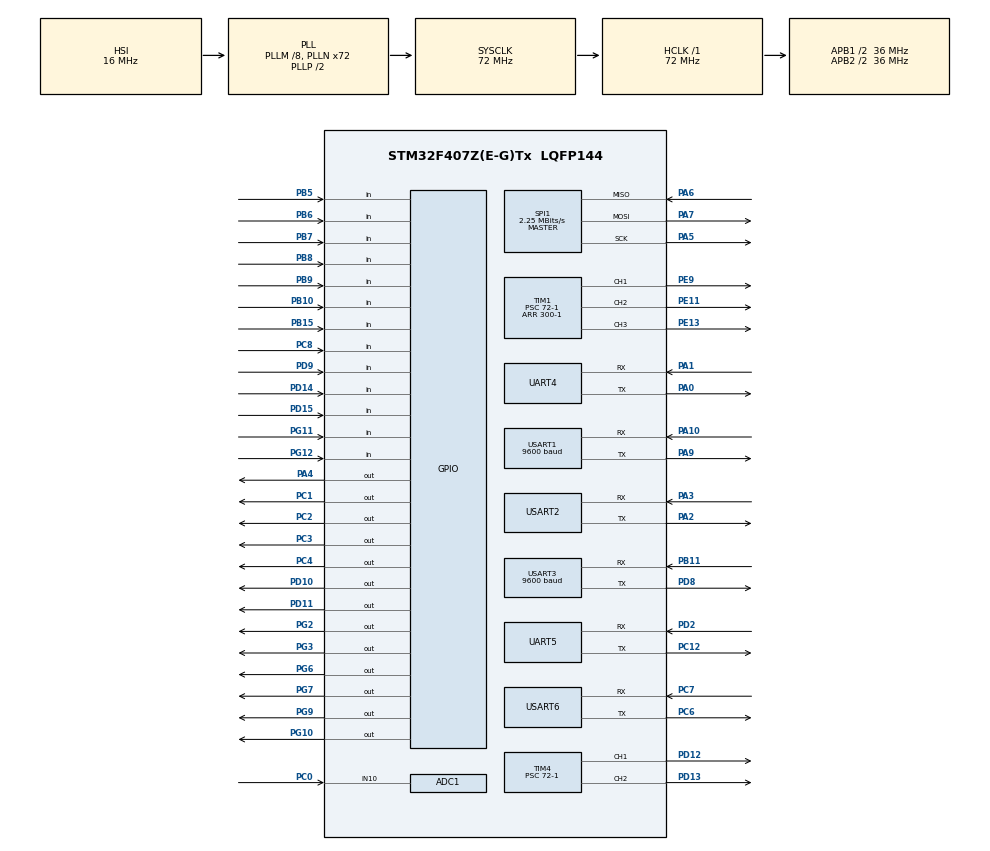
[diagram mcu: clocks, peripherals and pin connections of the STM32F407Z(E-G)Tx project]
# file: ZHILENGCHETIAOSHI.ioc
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ADC1.Channel-3\#ChannelRegularConversion=ADC_CHANNEL_10
ADC1.ContinuousConvMode=DISABLE
ADC1.NbrOfConversionFlag=1
ADC1.Rank-3\#ChannelRegularConversion=1
ADC1.SamplingTime-3\#ChannelRegularConversion=ADC_SAMPLETIME_3CYCLES
ADC1.master=1
Dma.Request0=USART2_RX
Dma.Request1=USART2_TX
Dma.Request2=UART5_RX
Dma.Request3=UART5_TX
Dma.Request4=UART4_RX
Dma.Request5=UART4_TX
Dma.Request6=USART6_RX
Dma.Request7=USART6_TX
Dma.UART4_RX.4.Direction=DMA_PERIPH_TO_MEMORY
Dma.UART4_RX.4.FIFOMode=DMA_FIFOMODE_DISABLE
Dma.UART4_RX.4.Instance=DMA1_Stream2
Dma.UART4_RX.4.MemDataAlignment=DMA_MDATAALIGN_BYTE
Dma.UART4_RX.4.MemInc=DMA_MINC_ENABLE
Dma.UART4_RX.4.Mode=DMA_NORMAL
Dma.UART4_RX.4.PeriphDataAlignment=DMA_PDATAALIGN_BYTE
Dma.UART4_RX.4.PeriphInc=DMA_PINC_DISABLE
Dma.UART4_RX.4.Priority=DMA_PRIORITY_LOW
Dma.UART4_TX.5.Direction=DMA_MEMORY_TO_PERIPH
Dma.UART4_TX.5.FIFOMode=DMA_FIFOMODE_DISABLE
Dma.UART4_TX.5.Instance=DMA1_Stream4
Dma.UART4_TX.5.MemDataAlignment=DMA_MDATAALIGN_BYTE
Dma.UART4_TX.5.MemInc=DMA_MINC_ENABLE
Dma.UART4_TX.5.Mode=DMA_NORMAL
Dma.UART4_TX.5.PeriphDataAlignment=DMA_PDATAALIGN_BYTE
Dma.UART4_TX.5.PeriphInc=DMA_PINC_DISABLE
Dma.UART4_TX.5.Priority=DMA_PRIORITY_LOW
Dma.UART5_RX.2.Direction=DMA_PERIPH_TO_MEMORY
Dma.UART5_RX.2.FIFOMode=DMA_FIFOMODE_DISABLE
Dma.UART5_RX.2.Instance=DMA1_Stream0
Dma.UART5_RX.2.MemDataAlignment=DMA_MDATAALIGN_BYTE
Dma.UART5_RX.2.MemInc=DMA_MINC_ENABLE
Dma.UART5_RX.2.Mode=DMA_NORMAL
Dma.UART5_RX.2.PeriphDataAlignment=DMA_PDATAALIGN_BYTE
Dma.UART5_RX.2.PeriphInc=DMA_PINC_DISABLE
Dma.UART5_RX.2.Priority=DMA_PRIORITY_LOW
Dma.UART5_TX.3.Direction=DMA_MEMORY_TO_PERIPH
Dma.UART5_TX.3.FIFOMode=DMA_FIFOMODE_DISABLE
Dma.UART5_TX.3.Instance=DMA1_Stream7
Dma.UART5_TX.3.MemDataAlignment=DMA_MDATAALIGN_BYTE
Dma.UART5_TX.3.MemInc=DMA_MINC_ENABLE
Dma.UART5_TX.3.Mode=DMA_NORMAL
Dma.UART5_TX.3.PeriphDataAlignment=DMA_PDATAALIGN_BYTE
Dma.UART5_TX.3.PeriphInc=DMA_PINC_DISABLE
Dma.UART5_TX.3.Priority=DMA_PRIORITY_LOW
Dma.USART2_RX.0.Direction=DMA_PERIPH_TO_MEMORY
Dma.USART2_RX.0.FIFOMode=DMA_FIFOMODE_DISABLE
Dma.USART2_RX.0.Instance=DMA1_Stream5
Dma.USART2_RX.0.MemDataAlignment=DMA_MDATAALIGN_BYTE
Dma.USART2_RX.0.MemInc=DMA_MINC_ENABLE
Dma.USART2_RX.0.Mode=DMA_NORMAL
Dma.USART2_RX.0.PeriphDataAlignment=DMA_PDATAALIGN_BYTE
Dma.USART2_RX.0.PeriphInc=DMA_PINC_DISABLE
Dma.USART2_RX.0.Priority=DMA_PRIORITY_LOW
Dma.USART2_TX.1.Direction=DMA_MEMORY_TO_PERIPH
Dma.USART2_TX.1.FIFOMode=DMA_FIFOMODE_DISABLE
Dma.USART2_TX.1.Instance=DMA1_Stream6
Dma.USART2_TX.1.MemDataAlignment=DMA_MDATAALIGN_BYTE
Dma.USART2_TX.1.MemInc=DMA_MINC_ENABLE
Dma.USART2_TX.1.Mode=DMA_NORMAL
Dma.USART2_TX.1.PeriphDataAlignment=DMA_PDATAALIGN_BYTE
Dma.USART2_TX.1.PeriphInc=DMA_PINC_DISABLE
Dma.USART2_TX.1.Priority=DMA_PRIORITY_LOW
Dma.USART6_RX.6.Direction=DMA_PERIPH_TO_MEMORY
Dma.USART6_RX.6.FIFOMode=DMA_FIFOMODE_DISABLE
Dma.USART6_RX.6.Instance=DMA2_Stream1
Dma.USART6_RX.6.MemDataAlignment=DMA_MDATAALIGN_BYTE
Dma.USART6_RX.6.MemInc=DMA_MINC_ENABLE
Dma.USART6_RX.6.Mode=DMA_NORMAL
Dma.USART6_RX.6.PeriphDataAlignment=DMA_PDATAALIGN_BYTE
Dma.USART6_RX.6.PeriphInc=DMA_PINC_DISABLE
Dma.USART6_RX.6.Priority=DMA_PRIORITY_LOW
Dma.USART6_TX.7.Direction=DMA_MEMORY_TO_PERIPH
Dma.USART6_TX.7.FIFOMode=DMA_FIFOMODE_DISABLE
Dma.USART6_TX.7.Instance=DMA2_Stream6
Dma.USART6_TX.7.MemDataAlignment=DMA_MDATAALIGN_BYTE
Dma.USART6_TX.7.MemInc=DMA_MINC_ENABLE
Dma.USART6_TX.7.Mode=DMA_NORMAL
Dma.USART6_TX.7.PeriphDataAlignment=DMA_PDATAALIGN_BYTE
Dma.USART6_TX.7.PeriphInc=DMA_PINC_DISABLE
Dma.USART6_TX.7.Priority=DMA_PRIORITY_LOW
Mcu.Family=STM32F4
Mcu.Name=STM32F407Z(E-G)Tx
Mcu.Package=LQFP144
NVIC.DMA1_Stream0_IRQn=true\:0\:0\:false\:false\:true\:false\:true\:true
NVIC.DMA1_Stream2_IRQn=true\:0\:0\:false\:false\:true\:false\:true\:true
NVIC.DMA1_Stream4_IRQn=true\:0\:0\:false\:false\:true\:false\:true\:true
NVIC.DMA1_Stream5_IRQn=true\:0\:0\:false\:false\:true\:false\:true\:true
NVIC.DMA1_Stream6_IRQn=true\:0\:0\:false\:false\:true\:false\:true\:true
NVIC.DMA1_Stream7_IRQn=true\:0\:0\:false\:false\:true\:false\:true\:true
NVIC.DMA2_Stream1_IRQn=true\:0\:0\:false\:false\:true\:false\:true\:true
NVIC.DMA2_Stream6_IRQn=true\:0\:0\:false\:false\:true\:false\:true\:true
NVIC.PriorityGroup=NVIC_PRIORITYGROUP_4
NVIC.TIM7_IRQn=true\:15\:0\:false\:false\:true\:false\:true\:true
NVIC.TimeBase=TIM7_IRQn
NVIC.TimeBaseIP=TIM7
NVIC.UART4_IRQn=true\:0\:0\:false\:false\:true\:true\:true\:true
NVIC.UART5_IRQn=true\:0\:0\:false\:false\:true\:true\:true\:true
NVIC.USART1_IRQn=true\:0\:0\:false\:false\:true\:true\:true\:true
NVIC.USART2_IRQn=true\:0\:0\:false\:false\:true\:true\:true\:true
NVIC.USART6_IRQn=true\:0\:0\:false\:false\:true\:true\:true\:true
PA0-WKUP.Mode=Asynchronous
PA0-WKUP.Signal=UART4_TX
PA1.Mode=Asynchronous
PA1.Signal=UART4_RX
PA10.Mode=Asynchronous
PA10.Signal=USART1_RX
PA13.Mode=Serial_Wire
PA13.Signal=SYS_JTMS-SWDIO
PA14.Mode=Serial_Wire
PA14.Signal=SYS_JTCK-SWCLK
PA2.Mode=Asynchronous
PA2.Signal=USART2_TX
PA3.Mode=Asynchronous
PA3.Signal=USART2_RX
PA4.Signal=GPIO_Output
PA5.Mode=Full_Duplex_Master
PA5.Signal=SPI1_SCK
PA6.Mode=Full_Duplex_Master
PA6.Signal=SPI1_MISO
PA7.Mode=Full_Duplex_Master
PA7.Signal=SPI1_MOSI
PA9.Mode=Asynchronous
PA9.Signal=USART1_TX
PB10.Signal=GPIO_Input
PB11.Mode=Asynchronous
PB11.Signal=USART3_RX
PB15.Signal=GPIO_Input
PB5.Signal=GPIO_Input
PB6.Signal=GPIO_Input
PB7.Signal=GPIO_Input
PB8.Signal=GPIO_Input
PB9.Signal=GPIO_Input
PC0.Signal=ADCx_IN10
PC1.Signal=GPIO_Output
PC12.Mode=Asynchronous
PC12.Signal=UART5_TX
PC2.Signal=GPIO_Output
PC3.Signal=GPIO_Output
PC4.Signal=GPIO_Output
PC6.Mode=Asynchronous
PC6.Signal=USART6_TX
PC7.Mode=Asynchronous
PC7.Signal=USART6_RX
PC8.Signal=GPIO_Input
PD10.Signal=GPIO_Output
PD11.Signal=GPIO_Output
PD12.Signal=S_TIM4_CH1
PD13.Signal=S_TIM4_CH2
PD14.GPIO_PuPd=GPIO_PULLUP
PD14.Signal=GPIO_Input
PD15.GPIO_PuPd=GPIO_PULLUP
PD15.Signal=GPIO_Input
PD2.Mode=Asynchronous
PD2.Signal=UART5_RX
PD8.Mode=Asynchronous
PD8.Signal=USART3_TX
PD9.Signal=GPIO_Input
PE11.Signal=S_TIM1_CH2
PE13.Signal=S_TIM1_CH3
PE9.Signal=S_TIM1_CH1
PG10.Signal=GPIO_Output
PG11.GPIO_PuPd=GPIO_PULLUP
PG11.Signal=GPIO_Input
PG12.GPIO_PuPd=GPIO_PULLUP
PG12.Signal=GPIO_Input
PG2.Signal=GPIO_Output
PG3.Signal=GPIO_Output
PG6.Signal=GPIO_Output
PG7.Signal=GPIO_Output
PG9.Signal=GPIO_Output
PH0-OSC_IN.Mode=HSE-External-Oscillator
PH0-OSC_IN.Signal=RCC_OSC_IN
PH1-OSC_OUT.Mode=HSE-External-Oscillator
PH1-OSC_OUT.Signal=RCC_OSC_OUT
ProjectManager.HeapSize=0x200
ProjectManager.StackSize=0x400
ProjectManager.TargetToolchain=STM32CubeIDE
RCC.48MHZClocksFreq_Value=36000000
RCC.AHBFreq_Value=72000000
RCC.APB1CLKDivider=RCC_HCLK_DIV2
RCC.APB1Freq_Value=36000000
RCC.APB1TimFreq_Value=72000000
RCC.APB2CLKDivider=RCC_HCLK_DIV2
RCC.APB2Freq_Value=36000000
RCC.APB2TimFreq_Value=72000000
RCC.CortexFreq_Value=72000000
RCC.HCLKFreq_Value=72000000
RCC.HSE_VALUE=25000000
RCC.HSI_VALUE=16000000
RCC.LSE_VALUE=32768
RCC.PLLM=8
RCC.PLLN=72
RCC.SYSCLKFreq_VALUE=72000000
RCC.SYSCLKSource=RCC_SYSCLKSOURCE_PLLCLK
RCC.VCOOutputFreq_Value=144000000
SH.ADCx_IN10.0=ADC1_IN10,IN10
SH.S_TIM1_CH1.0=TIM1_CH1,PWM Generation1 CH1
SH.S_TIM1_CH2.0=TIM1_CH2,PWM Generation2 CH2
SH.S_TIM1_CH3.0=TIM1_CH3,PWM Generation3 CH3
SH.S_TIM4_CH1.0=TIM4_CH1,PWM Generation1 CH1
SH.S_TIM4_CH2.0=TIM4_CH2,PWM Generation2 CH2
SPI1.BaudRatePrescaler=SPI_BAUDRATEPRESCALER_16
SPI1.CLKPhase=SPI_PHASE_2EDGE
SPI1.CLKPolarity=SPI_POLARITY_HIGH
SPI1.CalculateBaudRate=2.25 MBits/s
SPI1.Direction=SPI_DIRECTION_2LINES
SPI1.Mode=SPI_MODE_MASTER
SPI1.VirtualType=VM_MASTER
TIM1.Channel-PWM\ Generation1\ CH1=TIM_CHANNEL_1
TIM1.Channel-PWM\ Generation2\ CH2=TIM_CHANNEL_2
TIM1.Channel-PWM\ Generation3\ CH3=TIM_CHANNEL_3
TIM1.CounterMode=TIM_COUNTERMODE_UP
TIM1.Period=300-1
TIM1.Prescaler=72-1
TIM2.Period=65535
TIM2.Prescaler=72-1
TIM4.Channel-PWM\ Generation1\ CH1=TIM_CHANNEL_1
TIM4.Channel-PWM\ Generation2\ CH2=TIM_CHANNEL_2
TIM4.Period=300-1
TIM4.Prescaler=72-1
TIM5.Period=50000
TIM5.Prescaler=7200-1
TIM6.Period=50000-1
TIM6.Prescaler=7200-1
TIM8.Period=65535
TIM8.Prescaler=72-1
TIM9.Period=50000
TIM9.Prescaler=7200-1
UART4.VirtualMode=Asynchronous
UART5.VirtualMode=Asynchronous
USART1.BaudRate=9600
USART1.VirtualMode=VM_ASYNC
USART2.VirtualMode=VM_ASYNC
USART3.BaudRate=9600
USART3.VirtualMode=VM_ASYNC
USART6.VirtualMode=VM_ASYNC
VP_SYS_VS_tim7.Mode=TIM7
VP_TIM1_VS_ClockSourceINT.Mode=Internal
VP_TIM2_VS_ClockSourceINT.Mode=Internal
VP_TIM2_VS_OPM.Mode=OPM_bit
VP_TIM4_VS_ClockSourceINT.Mode=Internal
VP_TIM5_VS_ClockSourceINT.Mode=Internal
VP_TIM6_VS_ClockSourceINT.Mode=Enable_Timer
VP_TIM8_VS_ClockSourceINT.Mode=Internal
VP_TIM9_VS_ClockSourceINT.Mode=Internal
board=custom

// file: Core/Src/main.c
/* USER CODE BEGIN Header */
/**
******************************************************************************
* @file : main.c
* @brief : Main program body
******************************************************************************
* @attention
*
* Copyright (c) 2025 STMicroelectronics.
* All rights reserved.
*
* This software is licensed under terms that can be found in the LICENSE file
* in the root directory of this software component.
* If no LICENSE file comes with this software, it is provided AS-IS.
*
******************************************************************************
*/
/* USER CODE END Header */
#include "main.h"
#include "adc.h"
#include "dma.h"
#include "spi.h"
#include "tim.h"
#include "usart.h"
#include "gpio.h"
#include "freertos_demo.h"
#include "FreeRTOS.h"					//FreeRTOS使用
#include "msd.h"
#include "ff.h"
#include "task.h"
#include "sys.h"
#include "data_send.h"
#include "start_init.h"
#include "my_RTC.h"
/* USER CODE BEGIN Includes */
//extern timestruction_for_wave time_for_wave,time_for_data;
/* USER CODE END Includes */
uint8_t ret = 1;
/* USER CODE BEGIN PTD */

uint8_t str_rec[600];
uint8_t str5_rec[300];
extern uint8_t ble_rx_buffer[300];
uint16_t dis_connect=0;
uint8_t print_rec[10];
/* USER CODE END PTD */

void SystemClock_Config(void);

int main(void)
{

  /* USER CODE BEGIN 1 */
	__disable_irq();                // 设置前关闭中断
	SCB->VTOR = 0x08008000;        // 替换成您的 APP 起始地址
	__enable_irq();                 // 恢复中断
  /* USER CODE END 1 */

  /* MCU Configuration--------------------------------------------------------*/

  /* Reset of all peripherals, Initializes the Flash interface and the Systick. */
  HAL_Init();

  /* Configure the system clock */
  SystemClock_Config();

  /* Initialize all configured peripherals */
  MX_GPIO_Init();
  MX_DMA_Init();
  MX_USART1_UART_Init();
  MX_SPI1_Init();
  MX_UART4_Init();
  MX_UART5_Init();
  MX_USART2_UART_Init();
  MX_USART3_UART_Init();
  MX_USART6_UART_Init();
  MX_TIM1_Init();
  MX_TIM2_Init();
  MX_TIM5_Init();
  MX_TIM6_Init();
  MX_TIM8_Init();
  MX_TIM9_Init();
  MX_ADC1_Init();
  MX_TIM4_Init();
  RTC_Init();
  /* USER CODE BEGIN 2 */
//  HAL_UART_Transmit(&huart1, (uint8_t*)"APP3 OK\r\n", 9, 100);
  Start_fuc();
  HAL_UARTEx_ReceiveToIdle_IT(&huart1,print_rec,10);
  HAL_UARTEx_ReceiveToIdle_DMA(&huart2,str_rec,sizeof(str_rec));
  HAL_UARTEx_ReceiveToIdle_DMA(&huart6, ble_rx_buffer, 300);
  freertos_demo();
  /* USER CODE END 2 */

  /* Infinite loop */
  /* USER CODE BEGIN WHILE */
  // while (1)
  // {
    /* USER CODE END WHILE */

    /* USER CODE BEGIN 3 */
  // }
  /* USER CODE END 3 */
}

void SystemClock_Config(void)
{
  RCC_OscInitTypeDef RCC_OscInitStruct = {0};
  RCC_ClkInitTypeDef RCC_ClkInitStruct = {0};

  /** Configure the main internal regulator output voltage
  */
  __HAL_RCC_PWR_CLK_ENABLE();
  __HAL_PWR_VOLTAGESCALING_CONFIG(PWR_REGULATOR_VOLTAGE_SCALE1);

  /** Initializes the RCC Oscillators according to the specified parameters
  * in the RCC_OscInitTypeDef structure.
  */
  RCC_OscInitStruct.OscillatorType = RCC_OSCILLATORTYPE_HSI;
  RCC_OscInitStruct.HSIState = RCC_HSI_ON;
  RCC_OscInitStruct.HSICalibrationValue = RCC_HSICALIBRATION_DEFAULT;
  RCC_OscInitStruct.PLL.PLLState = RCC_PLL_ON;
  RCC_OscInitStruct.PLL.PLLSource = RCC_PLLSOURCE_HSI;
  RCC_OscInitStruct.PLL.PLLM = 8;
  RCC_OscInitStruct.PLL.PLLN = 72;
  RCC_OscInitStruct.PLL.PLLP = RCC_PLLP_DIV2;
  RCC_OscInitStruct.PLL.PLLQ = 4;
  if (HAL_RCC_OscConfig(&RCC_OscInitStruct) != HAL_OK)
  {
    Error_Handler();
  }

  /** Initializes the CPU, AHB and APB buses clocks
  */
  RCC_ClkInitStruct.ClockType = RCC_CLOCKTYPE_HCLK|RCC_CLOCKTYPE_SYSCLK
                              |RCC_CLOCKTYPE_PCLK1|RCC_CLOCKTYPE_PCLK2;
  RCC_ClkInitStruct.SYSCLKSource = RCC_SYSCLKSOURCE_PLLCLK;
  RCC_ClkInitStruct.AHBCLKDivider = RCC_SYSCLK_DIV1;
  RCC_ClkInitStruct.APB1CLKDivider = RCC_HCLK_DIV2;
  RCC_ClkInitStruct.APB2CLKDivider = RCC_HCLK_DIV2;

  if (HAL_RCC_ClockConfig(&RCC_ClkInitStruct, FLASH_LATENCY_2) != HAL_OK)
  {
    Error_Handler();
  }
}

void HAL_TIM_PeriodElapsedCallback(TIM_HandleTypeDef *htim)
{
  if (htim->Instance == TIM7)
  {
    HAL_IncTick();
  }
}

void Error_Handler(void)
{
  __disable_irq();
  while (1)
  {
  }
}
